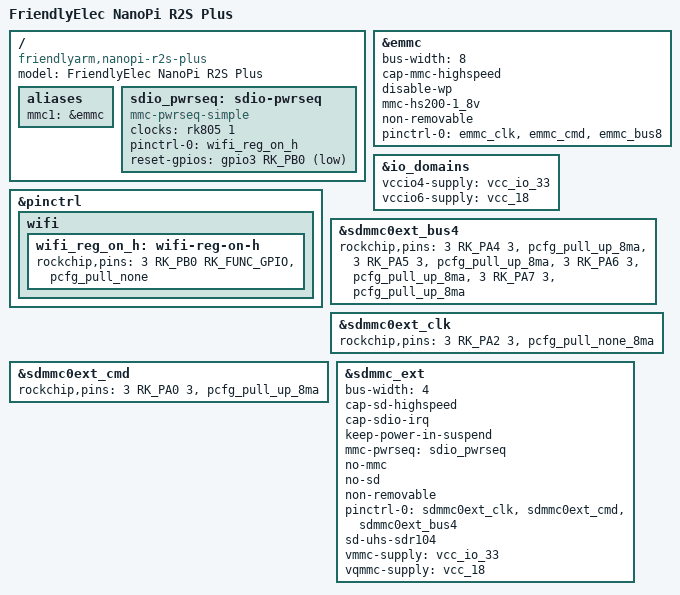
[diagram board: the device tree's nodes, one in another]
// SPDX-License-Identifier: (GPL-2.0+ OR MIT)
/*
 * (C) Copyright 2018 FriendlyElec Computer Tech. Co., Ltd.
 * (http://www.friendlyarm.com)
 *
 * (C) Copyright 2016 Rockchip Electronics Co., Ltd
 */

/dts-v1/;

#include "rk3328-nanopi-r2s.dtsi"

/ {
	compatible = "friendlyarm,nanopi-r2s-plus", "rockchip,rk3328";
	model = "FriendlyElec NanoPi R2S Plus";

	aliases {
		mmc1 = &emmc;
	};

	sdio_pwrseq: sdio-pwrseq {
		compatible = "mmc-pwrseq-simple";
		clocks = <&rk805 1>;
		clock-names = "ext_clock";
		pinctrl-names = "default";
		pinctrl-0 = <&wifi_reg_on_h>;
		reset-gpios = <&gpio3 RK_PB0 GPIO_ACTIVE_LOW>;
	};
};

&emmc {
	bus-width = <8>;
	cap-mmc-highspeed;
	disable-wp;
	mmc-hs200-1_8v;
	non-removable;
	pinctrl-names = "default";
	pinctrl-0 = <&emmc_clk &emmc_cmd &emmc_bus8>;
	status = "okay";
};

&io_domains {
	vccio4-supply = <&vcc_io_33>;
	vccio6-supply = <&vcc_18>;
};

&pinctrl {
	wifi {
		wifi_reg_on_h: wifi-reg-on-h {
			rockchip,pins = <3 RK_PB0 RK_FUNC_GPIO &pcfg_pull_none>;
		};
	};
};

/*
 * SDR104 tuning fails with the default 4mA drive strength, use 8mA like the
 * vendor device tree.
 */
&sdmmc0ext_bus4 {
	rockchip,pins =
		<3 RK_PA4 3 &pcfg_pull_up_8ma>,
		<3 RK_PA5 3 &pcfg_pull_up_8ma>,
		<3 RK_PA6 3 &pcfg_pull_up_8ma>,
		<3 RK_PA7 3 &pcfg_pull_up_8ma>;
};

&sdmmc0ext_clk {
	rockchip,pins = <3 RK_PA2 3 &pcfg_pull_none_8ma>;
};

&sdmmc0ext_cmd {
	rockchip,pins = <3 RK_PA0 3 &pcfg_pull_up_8ma>;
};

/* Optional M.2 E-key SDIO Wi-Fi module (Fn-Link 6222B-SRC, RTL8822CS) */
&sdmmc_ext {
	bus-width = <4>;
	cap-sd-highspeed;
	cap-sdio-irq;
	keep-power-in-suspend;
	mmc-pwrseq = <&sdio_pwrseq>;
	no-mmc;
	no-sd;
	non-removable;
	pinctrl-names = "default";
	pinctrl-0 = <&sdmmc0ext_clk &sdmmc0ext_cmd &sdmmc0ext_bus4>;
	sd-uhs-sdr104;
	vmmc-supply = <&vcc_io_33>;
	vqmmc-supply = <&vcc_18>;
	status = "okay";
};
